AUTOSAR XML (schema 00051)
package /ComponentTypes
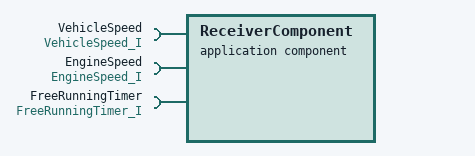
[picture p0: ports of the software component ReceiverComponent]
  application sw component type ReceiverComponent
    require port VehicleSpeed: nonqueued-receiver-com-spec{data-element=VehicleSpeed, init-value=constant-reference=VehicleSpeed_IV}, required-interface=VehicleSpeed_I
    require port EngineSpeed: nonqueued-receiver-com-spec{data-element=EngineSpeed, init-value=constant-reference=EngineSpeed_IV}, required-interface=EngineSpeed_I
    require port FreeRunningTimer: required-com-specs=[GetTime, IsTimerElapsed], required-interface=FreeRunningTimer_I
  application sw component type TimerComponent
    provide port FreeRunningTimer: provided-com-specs=[{operation=GetTime, queue-length=1}, {operation=IsTimerElapsed, queue-length=1}], provided-interface=FreeRunningTimer_I
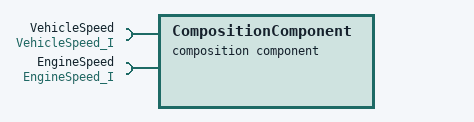
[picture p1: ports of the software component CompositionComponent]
  composition sw component type CompositionComponent
    require port VehicleSpeed: nonqueued-receiver-com-spec{data-element=VehicleSpeed, init-value=constant-reference=VehicleSpeed_IV}, required-interface=VehicleSpeed_I
    require port EngineSpeed: nonqueued-receiver-com-spec{data-element=EngineSpeed, init-value=constant-reference=EngineSpeed_IV}, required-interface=EngineSpeed_I
    component ReceiverComponent: type=ReceiverComponent
    component TimerComponent: type=TimerComponent
    connect TimerComponent.FreeRunningTimer -> ReceiverComponent.FreeRunningTimer
    delegate ReceiverComponent.VehicleSpeed <-> outer port CompositionComponent/VehicleSpeed
    delegate ReceiverComponent.EngineSpeed <-> outer port CompositionComponent/EngineSpeed
